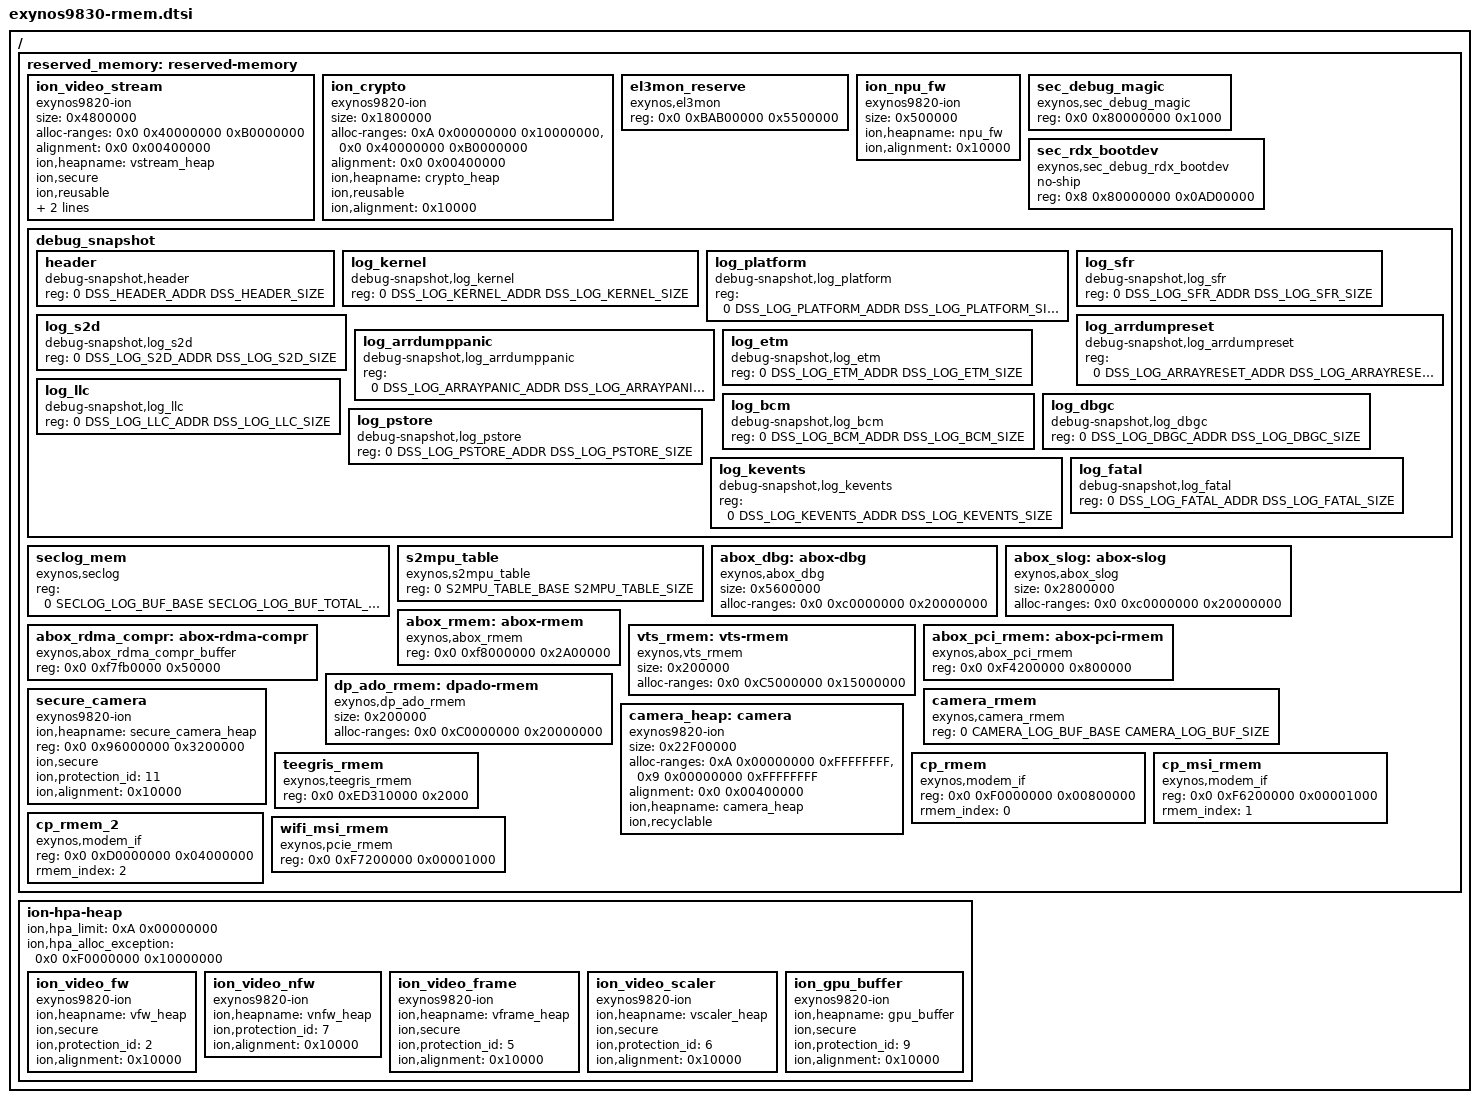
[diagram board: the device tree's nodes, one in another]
/*
 * SAMSUNG EXYNOS device tree source for reserved-memory
 *
 * Copyright (c) 2015 Samsung Electronics Co., Ltd.
 *		http://www.samsung.com
 *
 * This program is free software; you can redistribute it and/or modify
 * it under the terms of the GNU General Public License version 2 as
 * published by the Free Software Foundation.
 */

#include <dt-bindings/soc/samsung/debug-snapshot-def.h>
#include <dt-bindings/soc/samsung/exynos9830-seclog.h>
#include <dt-bindings/soc/samsung/exynos9830-s2mpu.h>
#include <dt-bindings/camera/exynos_is_dt.h>

/ {

	reserved_memory: reserved-memory {
		#address-cells = <2>;
		#size-cells = <1>;
		ranges;

		ion_video_stream {
			compatible = "exynos9820-ion";
			size = <0x4800000>;
			alloc-ranges = <0x0 0x40000000 0xB0000000>;
			alignment = <0x0 0x00400000>;
			ion,heapname = "vstream_heap";
			ion,secure;
			ion,reusable;
			ion,protection_id = <3>;
			ion,alignment = <0x10000>;
		};

		ion_crypto{
			compatible = "exynos9820-ion";
			size = <0x1800000>;
			alloc-ranges =	<0xA 0x00000000 0x10000000>,
					<0x0 0x40000000 0xB0000000>;
			alignment = <0x0 0x00400000>;
			ion,heapname = "crypto_heap";
			ion,reusable;
			ion,alignment = <0x10000>;
		};

		el3mon_reserve {
			compatible = "exynos,el3mon";
			reg = <0x0 0xBAB00000 0x5500000>;
		};

		ion_npu_fw {
			compatible = "exynos9820-ion";
			size = <0x500000>;
			/*alloc-ranges = <0x0 0x88000000 0x500000>;*/
			ion,heapname = "npu_fw";
			ion,alignment = <0x10000>;
		};

		sec_debug_magic {
			compatible = "exynos,sec_debug_magic";
			reg = <0x0 0x80000000 0x1000>;
		};

		sec_rdx_bootdev {
			compatible = "exynos,sec_debug_rdx_bootdev";
			no-ship;
			reg = <0x8 0x80000000 0x0AD00000>;
		};

		debug_snapshot {
			#address-cells = <2>;
			#size-cells = <1>;

			header {
				compatible = "debug-snapshot,header";
				reg = <0 DSS_HEADER_ADDR DSS_HEADER_SIZE>;
			};
			log_kernel {
				compatible = "debug-snapshot,log_kernel";
				reg = <0 DSS_LOG_KERNEL_ADDR DSS_LOG_KERNEL_SIZE>;
			};
			log_platform {
				compatible = "debug-snapshot,log_platform";
				reg = <0 DSS_LOG_PLATFORM_ADDR DSS_LOG_PLATFORM_SIZE>;
			};
			log_sfr {
				compatible = "debug-snapshot,log_sfr";
				reg = <0 DSS_LOG_SFR_ADDR DSS_LOG_SFR_SIZE>;
			};
			log_s2d {
				compatible = "debug-snapshot,log_s2d";
				reg = <0 DSS_LOG_S2D_ADDR DSS_LOG_S2D_SIZE>;
			};
			log_arrdumpreset {
				compatible = "debug-snapshot,log_arrdumpreset";
				reg = <0 DSS_LOG_ARRAYRESET_ADDR DSS_LOG_ARRAYRESET_SIZE>;
			};
			log_arrdumppanic {
				compatible = "debug-snapshot,log_arrdumppanic";
				reg = <0 DSS_LOG_ARRAYPANIC_ADDR DSS_LOG_ARRAYPANIC_SIZE>;
			};
			log_etm {
				compatible = "debug-snapshot,log_etm";
				reg = <0 DSS_LOG_ETM_ADDR DSS_LOG_ETM_SIZE>;
			};
			log_bcm {
				compatible = "debug-snapshot,log_bcm";
				reg = <0 DSS_LOG_BCM_ADDR DSS_LOG_BCM_SIZE>;
			};
			log_llc {
				compatible = "debug-snapshot,log_llc";
				reg = <0 DSS_LOG_LLC_ADDR DSS_LOG_LLC_SIZE>;
			};
			log_dbgc {
				compatible = "debug-snapshot,log_dbgc";
				reg = <0 DSS_LOG_DBGC_ADDR DSS_LOG_DBGC_SIZE>;
			};
			log_pstore {
				compatible = "debug-snapshot,log_pstore";
				reg = <0 DSS_LOG_PSTORE_ADDR DSS_LOG_PSTORE_SIZE>;
			};
			log_kevents {
				compatible = "debug-snapshot,log_kevents";
				reg = <0 DSS_LOG_KEVENTS_ADDR DSS_LOG_KEVENTS_SIZE>;
			};
			log_fatal {
				compatible = "debug-snapshot,log_fatal";
				reg = <0 DSS_LOG_FATAL_ADDR DSS_LOG_FATAL_SIZE>;
			};
		};

		seclog_mem {
			compatible = "exynos,seclog";
			reg = <0 SECLOG_LOG_BUF_BASE SECLOG_LOG_BUF_TOTAL_SIZE>;
		};

		s2mpu_table {
			compatible = "exynos,s2mpu_table";
			reg = <0 S2MPU_TABLE_BASE S2MPU_TABLE_SIZE>;
		};

		abox_dbg: abox-dbg {
			compatible = "exynos,abox_dbg";
			size = <0x5600000>;
			alloc-ranges = <0x0 0xc0000000 0x20000000>;
		};

		abox_slog: abox-slog {
			compatible = "exynos,abox_slog";
			size = <0x2800000>;
			alloc-ranges = <0x0 0xc0000000 0x20000000>;
		};

		abox_rmem: abox-rmem {
			compatible = "exynos,abox_rmem";
			/* Linear area for low power.
			 * Size should be same with
			 * CONFIG_SND_SOC_SAMSUNG_ABOX_DRAM_SIZE.
			 */
			reg = <0x0 0xf8000000 0x2A00000>;
		};

		abox_rdma_compr: abox-rdma-compr {
			compatible = "exynos,abox_rdma_compr_buffer";
			reg = <0x0 0xf7fb0000 0x50000>;
		};

		vts_rmem: vts-rmem {
			compatible = "exynos,vts_rmem";
			size = <0x200000>;
			alloc-ranges = <0x0 0xC5000000 0x15000000>;
		};

		abox_pci_rmem: abox-pci-rmem {
			compatible = "exynos,abox_pci_rmem";
			reg = <0x0 0xF4200000 0x800000>;
		};

		dp_ado_rmem: dpado-rmem {
			compatible = "exynos,dp_ado_rmem";
			size = <0x200000>;
			alloc-ranges = <0x0 0xC0000000 0x20000000>;
		};

		camera_rmem: camera_rmem {
			compatible = "exynos,camera_rmem";
			reg = <0 CAMERA_LOG_BUF_BASE CAMERA_LOG_BUF_SIZE>;
		};

		secure_camera {
			compatible = "exynos9820-ion";
			ion,heapname = "secure_camera_heap";
			reg = <0x0 0x96000000 0x3200000>;
			ion,secure;
			ion,protection_id = <11>;
			ion,alignment = <0x10000>;
		};

		camera_heap: camera {
			compatible = "exynos9820-ion";
			size = <0x22F00000>;
			alloc-ranges =	<0xA 0x00000000 0xFFFFFFFF>,
					<0x9 0x00000000 0xFFFFFFFF>;
			alignment = <0x0 0x00400000>;
			ion,heapname = "camera_heap";
			ion,recyclable;
		};

		teegris_rmem: teegris_rmem {
			compatible = "exynos,teegris_rmem";
			reg = <0x0 0xED310000 0x2000>;
		};

		cp_rmem {
			compatible = "exynos,modem_if";
			reg = <0x0 0xF0000000 0x00800000>;
			rmem_index = <0>;
		};

		cp_msi_rmem {
			compatible = "exynos,modem_if";
			reg = <0x0 0xF6200000 0x00001000>;
			rmem_index = <1>;
		};

		cp_rmem_2 {
			compatible = "exynos,modem_if";
			reg = <0x0 0xD0000000 0x04000000>;
			rmem_index = <2>;
		};

		wifi_msi_rmem {
			compatible = "exynos,pcie_rmem";
			reg = <0x0 0xF7200000 0x00001000>;
		};
	};

	ion-hpa-heap {
		#address-cells = <2>;
		#size-cells = <1>;
		ranges;
		ion,hpa_limit = <0xA 0x00000000>;
		ion,hpa_alloc_exception = <0x0 0xF0000000 0x10000000>;
		ion_video_fw {
			compatible = "exynos9820-ion";
			ion,heapname = "vfw_heap";
			ion,secure;
			ion,protection_id = <2>;
			ion,alignment = <0x10000>;
		};

		ion_video_nfw {
			compatible = "exynos9820-ion";
			ion,heapname = "vnfw_heap";
			ion,protection_id = <7>;
			ion,alignment = <0x10000>;
		};

		ion_video_frame {
			compatible = "exynos9820-ion";
			ion,heapname = "vframe_heap";
			ion,secure;
			ion,protection_id = <5>;
			ion,alignment = <0x10000>;
		};

		ion_video_scaler {
			compatible = "exynos9820-ion";
			ion,heapname = "vscaler_heap";
			ion,secure;
			ion,protection_id = <6>;
			ion,alignment = <0x10000>;
		};

		ion_gpu_buffer {
			compatible = "exynos9820-ion";
			ion,heapname = "gpu_buffer";
			ion,secure;
			ion,protection_id = <9>;
			ion,alignment = <0x10000>;
		};
	};
};
